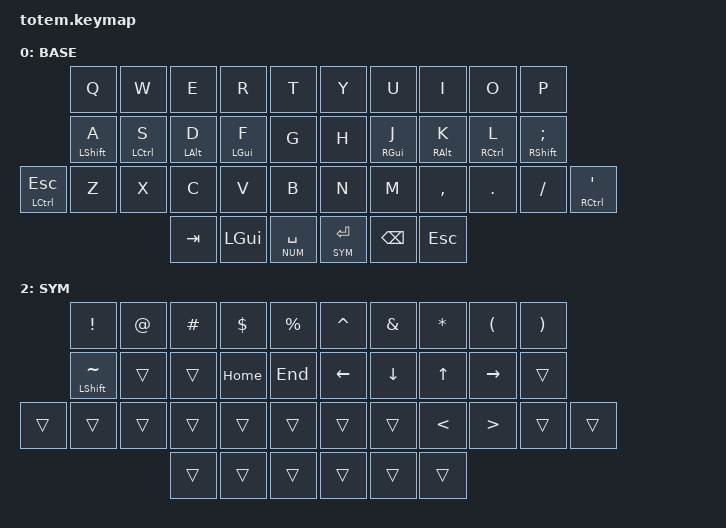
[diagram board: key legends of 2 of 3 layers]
//
//                                                        ▀▀▀▀▀     ▀▀▀▀▀         ▀▀█▀▀
//                                                        ▄▀▀▀▄  ▄  ▄▀▀▀▄  ▄  ▄▀▀▀▄  █  ▄▀▀▀▄
//                                                        █   █  █  █   █  █  █   █  █  █   █
//                                                         ▀▀▀   █   ▀▀▀   █   ▀▀▀   ▀   ▀▀▀
//                                                               █      ▄▄▄█▄▄▄    █   █  
//                                                               ▀      █  █  █     █▄█
//                                                             ▀▀▀▀▀    █  █  █      ▀
//                                                                      ▀  ▀  ▀
//
// ▄▄▄▄▄▄▄▄▄▄▄▄▄▄▄▄▄▄▄▄▄▄▄▄▄▄▄▄▄▄▄▄▄▄▄▄▄▄▄▄▄▄▄▄▄▄▄▄▄▄▄▄▄▄▄▄▄▄▄▄▄▄▄▄▄▄▄▄▄▄▄▄▄▄▄▄▄▄▄▄▄▄▄▄▄▄▄▄▄▄▄▄▄▄▄▄▄▄▄▄▄▄▄▄▄▄▄▄▄▄▄▄▄▄▄▄▄▄▄▄▄▄▄▄▄▄▄▄▄▄▄▄▄▄▄▄▄▄▄▄▄▄▄▄▄▄▄▄▄
       

#include <behaviors.dtsi>
#include <dt-bindings/zmk/keys.h>
#include <dt-bindings/zmk/bt.h>
#include <dt-bindings/zmk/outputs.h>

#define BASE 0
#define NUM  1
#define SYM  2

&mt {
  quick-tap-ms = <100>;
  require-prior-idle-ms = <125>;
  flavor = "tap-preferred";
  tapping-term-ms = <170>;
};

&lt {
  quick-tap-ms = <150>;
  tapping-term-ms = <170>;
};

/ {
    combos {
        compatible = "zmk,combos";
        combo_esc {
            timeout-ms = <50>;
            key-positions = <0 1>;
            bindings = <&kp ESC>;
        };
    };

    keymap {
        compatible = "zmk,keymap";
// ▄▄▄▄▄▄▄▄▄▄▄▄▄▄▄▄▄▄▄▄▄▄▄▄▄▄▄▄▄▄▄▄▄▄▄▄▄▄▄▄▄▄▄▄▄▄▄▄▄▄▄▄▄▄▄▄▄▄▄▄▄▄▄▄▄▄▄▄▄▄▄▄▄▄▄▄▄▄▄▄▄▄▄▄▄▄▄▄▄▄▄▄▄▄▄▄▄▄▄▄▄▄▄▄▄▄▄▄▄▄▄▄▄▄▄▄▄▄▄▄▄▄▄▄▄▄▄▄▄▄▄▄▄▄▄▄▄▄▄▄▄▄▄▄▄▄▄▄▄

        base_layer {
// ┏━━━━━━━━━━━━━━━━━━━━━━━━━━━━━━━━━━━━━━━┓
display-name = "BASE";
// ┗━━━━━━━━━━━━━━━━━━━━━━━━━━━━━━━━━━━━━━━┛
//             ┏━━━━━━━━━━━┳━━━━━━━━━━━┳━━━━━━━━━━━┳━━━━━━━━━━━┳━━━━━━━━━━━┓   ┏━━━━━━━━━━━┳━━━━━━━━━━━┳━━━━━━━━━━━┳━━━━━━━━━━━┳━━━━━━━━━━━┓
//             ┃     Q     ┃     W     ┃     E     ┃     R     ┃     T     ┃   ┃     Y     ┃     U     ┃     I     ┃     O     ┃     P     ┃
//             ┣━━━━━━━━━━━╋━━━━━━━━━━━╋━━━━━━━━━━━╋━━━━━━━━━━━╋━━━━━━━━━━━┫   ┣━━━━━━━━━━━╋━━━━━━━━━━━╋━━━━━━━━━━━╋━━━━━━━━━━━╋━━━━━━━━━━━┫
//             ┃  SHFT / A ┃  CTRL / S ┃  ALT / D  ┃  CMD / F  ┃     G     ┃   ┃     H     ┃  CMD / J  ┃  ALT / K  ┃  CTRL / L ┃  SHFT / ; ┃
// ┏━━━━━━━━━━━╋━━━━━━━━━━━╋━━━━━━━━━━━╋━━━━━━━━━━━╋━━━━━━━━━━━╋━━━━━━━━━━━┫   ┣━━━━━━━━━━━╋━━━━━━━━━━━╋━━━━━━━━━━━╋━━━━━━━━━━━╋━━━━━━━━━━━╋━━━━━━━━━━━┓
// ┃    ESC    ┃     Z     ┃     X     ┃     C     ┃     V     ┃     B     ┃   ┃     N     ┃     M     ┃     ,     ┃     .     ┃     /     ┃     '     ┃
// ┗━━━━━━━━━━━┻━━━━━━━━━━━┻━━━━━━━━━━━╋━━━━━━━━━━━╋━━━━━━━━━━━╋━━━━━━━━━━━┫   ┣━━━━━━━━━━━╋━━━━━━━━━━━╋━━━━━━━━━━━╋━━━━━━━━━━━┻━━━━━━━━━━━┻━━━━━━━━━━━┛
//                                     ┃    TAB    ┃    CMD    ┃   SPACE   ┃   ┃  SYM/RET  ┃   BSPC    ┃    ESC    ┃
//                                     ┗━━━━━━━━━━━┻━━━━━━━━━━━┻━━━━━━━━━━━┛   ┗━━━━━━━━━━━┻━━━━━━━━━━━┻━━━━━━━━━━━┛
            bindings = <
// ╷           ╷           ╷           ╷           ╷           ╷   ╷           ╷           ╷           ╷           ╷           ╷           ╷

                &kp Q       &kp W       &kp E       &kp R       &kp T           &kp Y       &kp U       &kp I       &kp O       &kp P
                &mt LSHFT A &mt LCTRL S &mt LALT D  &mt LGUI F  &kp G           &kp H       &mt RGUI J  &mt RALT K  &mt RCTRL L &mt RSHFT SEMI
&mt LCTRL ESC   &kp Z       &kp X       &kp C       &kp V       &kp B           &kp N       &kp M       &kp COMMA   &kp DOT     &kp FSLH    &mt RCTRL SQT 
                                        &kp TAB     &kp LGUI    &lt NUM SPACE   &lt SYM RET &kp BSPC    &kp ESC
            >;
        };

// ▄▄▄▄▄▄▄▄▄▄▄▄▄▄▄▄▄▄▄▄▄▄▄▄▄▄▄▄▄▄▄▄▄▄▄▄▄▄▄▄▄▄▄▄▄▄▄▄▄▄▄▄▄▄▄▄▄▄▄▄▄▄▄▄▄▄▄▄▄▄▄▄▄▄▄▄▄▄▄▄▄▄▄▄▄▄▄▄▄▄▄▄▄▄▄▄▄▄▄▄▄▄▄▄▄▄▄▄▄▄▄▄▄▄▄▄▄▄▄▄▄▄▄▄▄▄▄▄▄▄▄▄▄▄▄▄▄▄▄▄▄▄▄▄▄▄▄▄▄

        num_layer {
// ┏━━━━━━━━━━━━━━━━━━━━━━━━━━━━━━━━━━━━━━━┓
display-name = "NUM";
// ┗━━━━━━━━━━━━━━━━━━━━━━━━━━━━━━━━━━━━━━━┛
//             ┏━━━━━━━━━━━┳━━━━━━━━━━━┳━━━━━━━━━━━┳━━━━━━━━━━━┳━━━━━━━━━━━┓   ┏━━━━━━━━━━━┳━━━━━━━━━━━┳━━━━━━━━━━━┳━━━━━━━━━━━┳━━━━━━━━━━━┓
//             ┃     1     ┃     2     ┃     3     ┃     4     ┃     5     ┃   ┃     6     ┃     7     ┃     8     ┃     9     ┃     0     ┃
//             ┣━━━━━━━━━━━╋━━━━━━━━━━━╋━━━━━━━━━━━╋━━━━━━━━━━━╋━━━━━━━━━━━┫   ┣━━━━━━━━━━━╋━━━━━━━━━━━╋━━━━━━━━━━━╋━━━━━━━━━━━╋━━━━━━━━━━━┫
//             ┃  SHFT/`   ┃           ┃           ┃           ┃           ┃   ┃     [     ┃     ]     ┃     -     ┃     =     ┃     \     ┃
// ┏━━━━━━━━━━━╋━━━━━━━━━━━╋━━━━━━━━━━━╋━━━━━━━━━━━╋━━━━━━━━━━━╋━━━━━━━━━━━┫   ┣━━━━━━━━━━━╋━━━━━━━━━━━╋━━━━━━━━━━━╋━━━━━━━━━━━╋━━━━━━━━━━━╋━━━━━━━━━━━┓
// ┃           ┃           ┃           ┃           ┃           ┃           ┃   ┃           ┃           ┃           ┃           ┃           ┃           ┃
// ┗━━━━━━━━━━━┻━━━━━━━━━━━┻━━━━━━━━━━━╋━━━━━━━━━━━╋━━━━━━━━━━━╋━━━━━━━━━━━┫   ┣━━━━━━━━━━━╋━━━━━━━━━━━╋━━━━━━━━━━━╋━━━━━━━━━━━┻━━━━━━━━━━━┻━━━━━━━━━━━┛
//                                     ┃           ┃           ┃           ┃   ┃           ┃           ┃           ┃
//                                     ┗━━━━━━━━━━━┻━━━━━━━━━━━┻━━━━━━━━━━━┛   ┗━━━━━━━━━━━┻━━━━━━━━━━━┻━━━━━━━━━━━┛
            bindings = <
// ╷           ╷           ╷           ╷           ╷           ╷   ╷           ╷           ╷           ╷           ╷           ╷           ╷

                &kp N1      &kp N2      &kp N3      &kp N4      &kp N5          &kp N6      &kp N7      &kp N8      &kp N9      &kp N0
           &mt LSHIFT GRAVE &trans      &trans      &trans      &trans          &kp LBKT    &kp RBKT    &kp MINUS   &kp EQUAL   &kp BSLH
                &trans      &trans      &trans      &trans      &trans          &trans      &trans      &trans      &trans      &trans      &trans
                                        &trans      &trans      &trans          &trans      &trans      &trans
            >;
        };

// ▄▄▄▄▄▄▄▄▄▄▄▄▄▄▄▄▄▄▄▄▄▄▄▄▄▄▄▄▄▄▄▄▄▄▄▄▄▄▄▄▄▄▄▄▄▄▄▄▄▄▄▄▄▄▄▄▄▄▄▄▄▄▄▄▄▄▄▄▄▄▄▄▄▄▄▄▄▄▄▄▄▄▄▄▄▄▄▄▄▄▄▄▄▄▄▄▄▄▄▄▄▄▄▄▄▄▄▄▄▄▄▄▄▄▄▄▄▄▄▄▄▄▄▄▄▄▄▄▄▄▄▄▄▄▄▄▄▄▄▄▄▄▄▄▄▄▄▄▄

        sym_layer {
// ┏━━━━━━━━━━━━━━━━━━━━━━━━━━━━━━━━━━━━━━━┓
display-name = "SYM";
// ┗━━━━━━━━━━━━━━━━━━━━━━━━━━━━━━━━━━━━━━━┛
//             ┏━━━━━━━━━━━┳━━━━━━━━━━━┳━━━━━━━━━━━┳━━━━━━━━━━━┳━━━━━━━━━━━┓   ┏━━━━━━━━━━━┳━━━━━━━━━━━┳━━━━━━━━━━━┳━━━━━━━━━━━┳━━━━━━━━━━━┓
//             ┃     !     ┃     @     ┃     #     ┃     $     ┃     %     ┃   ┃     ^     ┃     &     ┃     *     ┃     (     ┃     )     ┃
//             ┣━━━━━━━━━━━╋━━━━━━━━━━━╋━━━━━━━━━━━╋━━━━━━━━━━━╋━━━━━━━━━━━┫   ┣━━━━━━━━━━━╋━━━━━━━━━━━╋━━━━━━━━━━━╋━━━━━━━━━━━╋━━━━━━━━━━━┫
//             ┃     ~     ┃           ┃           ┃   HOME    ┃    END    ┃   ┃   LEFT    ┃   DOWN    ┃    UP     ┃   RIGHT   ┃           ┃
// ┏━━━━━━━━━━━╋━━━━━━━━━━━╋━━━━━━━━━━━╋━━━━━━━━━━━╋━━━━━━━━━━━╋━━━━━━━━━━━┫   ┣━━━━━━━━━━━╋━━━━━━━━━━━╋━━━━━━━━━━━╋━━━━━━━━━━━╋━━━━━━━━━━━╋━━━━━━━━━━━┓
// ┃           ┃           ┃           ┃           ┃           ┃           ┃   ┃           ┃           ┃     <     ┃     >     ┃           ┃           ┃
// ┗━━━━━━━━━━━┻━━━━━━━━━━━┻━━━━━━━━━━━╋━━━━━━━━━━━╋━━━━━━━━━━━╋━━━━━━━━━━━┫   ┣━━━━━━━━━━━╋━━━━━━━━━━━╋━━━━━━━━━━━╋━━━━━━━━━━━┻━━━━━━━━━━━┻━━━━━━━━━━━┛
//                                     ┃           ┃           ┃           ┃   ┃           ┃           ┃           ┃
//                                     ┗━━━━━━━━━━━┻━━━━━━━━━━━┻━━━━━━━━━━━┛   ┗━━━━━━━━━━━┻━━━━━━━━━━━┻━━━━━━━━━━━┛
            bindings = <
// ╷           ╷           ╷           ╷           ╷           ╷   ╷           ╷           ╷           ╷           ╷           ╷           ╷

                &kp EXCL    &kp AT      &kp HASH    &kp DLLR    &kp PRCNT       &kp CARET   &kp AMPS    &kp ASTRK   &kp LPAR    &kp RPAR
           &mt LSHIFT TILDE &trans      &trans      &kp HOME    &kp END         &kp LEFT    &kp DOWN    &kp UP      &kp RIGHT   &trans
    &trans      &trans      &trans      &trans      &trans      &trans          &trans      &trans      &kp LT      &kp GT      &trans      &trans
                                        &trans      &trans      &trans          &trans      &trans      &trans
            >;
        };
    };
};
